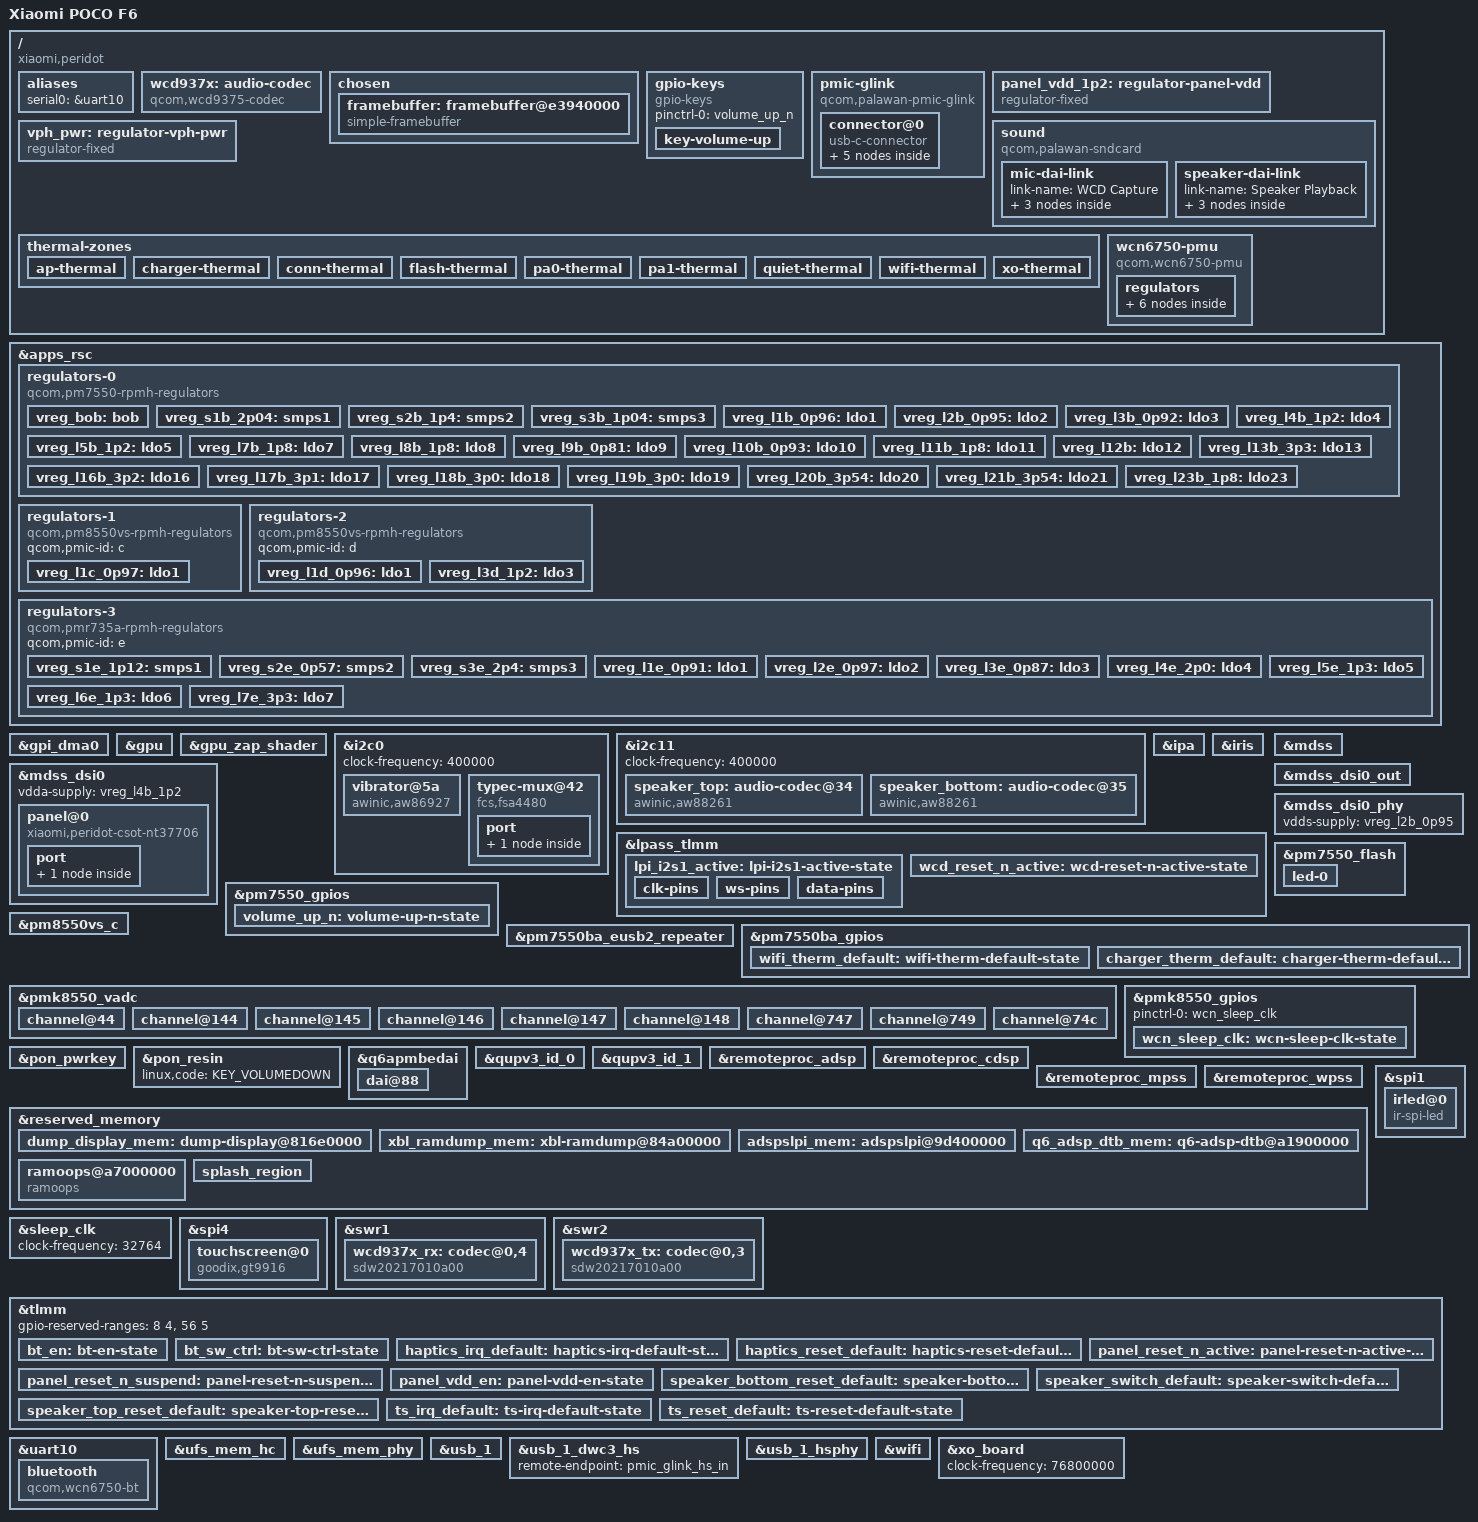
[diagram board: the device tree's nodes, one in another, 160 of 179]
// SPDX-License-Identifier: BSD-3-Clause
/*
 * Copyright (c) 2026, Yassin Rezai <yassinrsocial@proton.me>
 */

/dts-v1/;

#include <dt-bindings/arm/qcom,ids.h>
#include <dt-bindings/leds/common.h>
#include <dt-bindings/pinctrl/qcom,pmic-gpio.h>
#include <dt-bindings/regulator/qcom,rpmh-regulator.h>
#include <dt-bindings/sound/qcom,q6dsp-lpass-ports.h>
#include "palawan.dtsi"
#include "pm7550.dtsi" /* PMXR2230 */
#include "pm7550ba.dtsi"
#include "pmr735a.dtsi"
#define PMK8550VE_SID 3
#include "pm8550ve.dtsi"
#include "pm8550vs.dtsi"
#include "pmk8550.dtsi"

/delete-node/ &adspslpi_mem;
/delete-node/ &q6_adsp_dtb_mem;
/delete-node/ &xbl_ramdump_mem;

/ {
	model = "Xiaomi POCO F6";
	compatible = "xiaomi,peridot", "qcom,palawan";
	chassis-type = "handset";

	/*
	 * The bootloader uses an exact msm-id and board-id match to select
	 * this DTB and skip applying the vendor DTBO.
	 */
	qcom,msm-id = <QCOM_ID_SM8635 0x10000>;
	qcom,board-id = <8 0>;

	aliases {
		serial0 = &uart10;
	};

	wcd937x: audio-codec {
		compatible = "qcom,wcd9375-codec", "qcom,wcd9370-codec";

		reset-gpios = <&lpass_tlmm 12 GPIO_ACTIVE_LOW>;

		vdd-buck-supply = <&vreg_l7b_1p8>;
		vdd-rxtx-supply = <&vreg_l7b_1p8>;
		vdd-px-supply = <&vreg_l7b_1p8>;
		vdd-mic-bias-supply = <&vreg_bob>;

		qcom,micbias1-microvolt = <2750000>;
		qcom,micbias2-microvolt = <2750000>;
		qcom,micbias3-microvolt = <2750000>;
		qcom,micbias4-microvolt = <2750000>;

		qcom,rx-device = <&wcd937x_rx>;
		qcom,tx-device = <&wcd937x_tx>;

		pinctrl-0 = <&wcd_reset_n_active>;
		pinctrl-names = "default";

		#sound-dai-cells = <1>;
	};

	chosen {
		#address-cells = <2>;
		#size-cells = <2>;
		ranges;

		framebuffer: framebuffer@e3940000 {
			compatible = "simple-framebuffer";
			reg = <0x0 0xe3940000 0x0 (1220 * 2712 * 4)>;

			width = <1220>;
			height = <2712>;
			stride = <(1220 * 4)>;
			format = "a8r8g8b8";

			clocks = <&gcc GCC_DISP_HF_AXI_CLK>;
			interconnects = <&mmss_noc MASTER_MDP QCOM_ICC_TAG_ALWAYS
					 &mc_virt SLAVE_EBI1 QCOM_ICC_TAG_ALWAYS>;
			power-domains = <&rpmhpd RPMHPD_MMCX>;
		};
	};

	gpio-keys {
		compatible = "gpio-keys";

		pinctrl-0 = <&volume_up_n>;
		pinctrl-names = "default";

		key-volume-up {
			label = "Volume Up";
			linux,code = <KEY_VOLUMEUP>;
			gpios = <&pm7550_gpios 6 GPIO_ACTIVE_LOW>;
			debounce-interval = <15>;
			linux,can-disable;
			wakeup-source;
		};
	};

	pmic-glink {
		compatible = "qcom,palawan-pmic-glink",
			     "qcom,sm8550-pmic-glink",
			     "qcom,pmic-glink";
		#address-cells = <1>;
		#size-cells = <0>;

		connector@0 {
			compatible = "usb-c-connector";
			reg = <0>;

			power-role = "dual";
			data-role = "dual";

			ports {
				#address-cells = <1>;
				#size-cells = <0>;

				port@0 {
					reg = <0>;

					pmic_glink_hs_in: endpoint {
						remote-endpoint = <&usb_1_dwc3_hs>;
					};
				};

				port@2 {
					reg = <2>;

					pmic_glink_sbu: endpoint {
						remote-endpoint = <&fsa4480_sbu_mux>;
					};
				};
			};
		};
	};

	panel_vdd_1p2: regulator-panel-vdd {
		compatible = "regulator-fixed";

		regulator-name = "panel_vdd_1p2";
		regulator-min-microvolt = <1200000>;
		regulator-max-microvolt = <1200000>;

		gpio = <&tlmm 99 GPIO_ACTIVE_HIGH>;
		enable-active-high;
		regulator-boot-on;

		pinctrl-0 = <&panel_vdd_en>;
		pinctrl-names = "default";
	};

	vph_pwr: regulator-vph-pwr {
		compatible = "regulator-fixed";

		regulator-name = "vph_pwr";
		regulator-min-microvolt = <3700000>;
		regulator-max-microvolt = <3700000>;

		regulator-always-on;
		regulator-boot-on;
	};

	sound {
		compatible = "qcom,palawan-sndcard", "qcom,sm8450-sndcard";
		model = "Xiaomi-Peridot";

		pinctrl-0 = <&lpi_i2s1_active>, <&speaker_switch_default>;
		pinctrl-names = "default";

		audio-routing = "AMIC1", "MIC BIAS1",
				"AMIC2", "MIC BIAS2",
				"AMIC3", "MIC BIAS3",
				"AMIC4", "MIC BIAS3",
				"TX SWR_INPUT0", "ADC1_OUTPUT",
				"TX SWR_INPUT4", "ADC2_OUTPUT",
				"TX SWR_INPUT5", "ADC3_OUTPUT";

		mic-dai-link {
			link-name = "WCD Capture";

			cpu {
				sound-dai = <&q6apmbedai TX_CODEC_DMA_TX_3>;
			};

			codec {
				sound-dai = <&wcd937x 1>, <&swr2 1>, <&lpass_txmacro 0>;
			};

			platform {
				sound-dai = <&q6apm>;
			};
		};

		speaker-dai-link {
			link-name = "Speaker Playback";

			cpu {
				sound-dai = <&q6apmbedai QUINARY_TDM_RX_0>;

				dai-tdm-slot-num = <4>;
				dai-tdm-slot-width = <32>;
				dai-tdm-slot-rx-mask = <1 1 0 0>;
			};

			codec {
				sound-dai = <&speaker_top>, <&speaker_bottom>;

				dai-tdm-slot-num = <4>;
				dai-tdm-slot-width = <32>;
				dai-tdm-slot-rx-mask = <1 1 0 0>;
			};

			platform {
				sound-dai = <&q6apm>;
			};
		};
	};

	thermal-zones {
		ap-thermal {
			thermal-sensors = <&pmk8550_vadc ADC5_GEN3_AMUX2_THM_100K_PU(1)>;
		};

		charger-thermal {
			thermal-sensors = <&pmk8550_vadc ADC5_GEN3_AMUX6_THM_100K_PU(7)>;
		};

		conn-thermal {
			thermal-sensors = <&pmk8550_vadc ADC5_GEN3_AMUX4_THM_100K_PU(7)>;
		};

		flash-thermal {
			thermal-sensors = <&pmk8550_vadc ADC5_GEN3_AMUX5_THM_100K_PU(1)>;
		};

		pa0-thermal {
			thermal-sensors = <&pmk8550_vadc ADC5_GEN3_AMUX1_THM_100K_PU(1)>;
		};

		pa1-thermal {
			thermal-sensors = <&pmk8550_vadc ADC5_GEN3_AMUX3_THM_100K_PU(1)>;
		};

		quiet-thermal {
			thermal-sensors = <&pmk8550_vadc ADC5_GEN3_AMUX4_THM_100K_PU(1)>;
		};

		wifi-thermal {
			thermal-sensors = <&pmk8550_vadc ADC5_GEN3_AMUX3_GPIO_100K_PU(7)>;
		};

		xo-thermal {
			thermal-sensors = <&pmk8550_vadc ADC5_GEN3_AMUX1_THM_100K_PU(0)>;
		};
	};

	wcn6750-pmu {
		compatible = "qcom,wcn6750-pmu";

		pinctrl-0 = <&bt_en>, <&bt_sw_ctrl>;
		pinctrl-names = "default";

		vddio-supply = <&vreg_l7b_1p8>;
		vddaon-supply = <&vreg_s3b_1p04>;
		vddpmu-supply = <&vreg_s3b_1p04>;
		vddrfa0p8-supply = <&vreg_s3b_1p04>;
		vddrfa1p2-supply = <&vreg_s2b_1p4>;
		vddrfa1p7-supply = <&vreg_s1b_2p04>;
		vddrfa2p2-supply = <&vreg_s3e_2p4>;

		bt-enable-gpios = <&tlmm 156 GPIO_ACTIVE_HIGH>;
		swctrl-gpios = <&tlmm 80 GPIO_ACTIVE_HIGH>;

		regulators {
			vreg_pmu_rfa_cmn: ldo0 {
				regulator-name = "vreg_pmu_rfa_cmn";
			};

			vreg_pmu_aon: ldo1 {
				regulator-name = "vreg_pmu_aon";
			};

			vreg_pmu_btcmx: ldo4 {
				regulator-name = "vreg_pmu_btcmx";
			};

			vreg_pmu_rfa_0p8: ldo5 {
				regulator-name = "vreg_pmu_rfa_0p8";
			};

			vreg_pmu_rfa_1p2: ldo6 {
				regulator-name = "vreg_pmu_rfa_1p2";
			};

			vreg_pmu_rfa_1p7: ldo7 {
				regulator-name = "vreg_pmu_rfa_1p7";
			};
		};
	};
};

&apps_rsc {
	regulators-0 {
		compatible = "qcom,pm7550-rpmh-regulators";
		qcom,pmic-id = "b";

		vdd-bob-supply = <&vph_pwr>;

		vreg_bob: bob {
			regulator-name = "vreg_bob";
			regulator-min-microvolt = <3296000>;
			regulator-max-microvolt = <3960000>;
			regulator-initial-mode = <RPMH_REGULATOR_MODE_HPM>;
		};

		vreg_s1b_2p04: smps1 {
			regulator-name = "vreg_s1b_2p04";
			regulator-min-microvolt = <1856000>;
			regulator-max-microvolt = <2040000>;
			regulator-initial-mode = <RPMH_REGULATOR_MODE_HPM>;
		};

		vreg_s2b_1p4: smps2 {
			regulator-name = "vreg_s2b_1p4";
			regulator-min-microvolt = <1256000>;
			regulator-max-microvolt = <1408000>;
			regulator-initial-mode = <RPMH_REGULATOR_MODE_HPM>;
		};

		vreg_s3b_1p04: smps3 {
			regulator-name = "vreg_s3b_1p04";
			regulator-min-microvolt = <968000>;
			regulator-max-microvolt = <1040000>;
			regulator-initial-mode = <RPMH_REGULATOR_MODE_HPM>;
		};

		vreg_l1b_0p96: ldo1 {
			regulator-name = "vreg_l1b_0p96";
			regulator-min-microvolt = <880000>;
			regulator-max-microvolt = <960000>;
			regulator-initial-mode = <RPMH_REGULATOR_MODE_HPM>;
			regulator-allow-set-load;
			regulator-allowed-modes = <RPMH_REGULATOR_MODE_LPM
						   RPMH_REGULATOR_MODE_HPM>;
		};

		vreg_l2b_0p95: ldo2 {
			regulator-name = "vreg_l2b_0p95";
			regulator-min-microvolt = <880000>;
			regulator-max-microvolt = <952000>;
			regulator-initial-mode = <RPMH_REGULATOR_MODE_HPM>;
			regulator-allow-set-load;
			regulator-allowed-modes = <RPMH_REGULATOR_MODE_LPM
						   RPMH_REGULATOR_MODE_HPM>;
		};

		vreg_l3b_0p92: ldo3 {
			regulator-name = "vreg_l3b_0p92";
			regulator-min-microvolt = <880000>;
			regulator-max-microvolt = <920000>;
			regulator-initial-mode = <RPMH_REGULATOR_MODE_HPM>;
			regulator-allow-set-load;
			regulator-allowed-modes = <RPMH_REGULATOR_MODE_LPM
						   RPMH_REGULATOR_MODE_HPM>;
		};

		vreg_l4b_1p2: ldo4 {
			regulator-name = "vreg_l4b_1p2";
			regulator-min-microvolt = <1200000>;
			regulator-max-microvolt = <1200000>;
			regulator-initial-mode = <RPMH_REGULATOR_MODE_HPM>;
			regulator-allow-set-load;
			regulator-allowed-modes = <RPMH_REGULATOR_MODE_LPM
						   RPMH_REGULATOR_MODE_HPM>;
		};

		vreg_l5b_1p2: ldo5 {
			regulator-name = "vreg_l5b_1p2";
			regulator-min-microvolt = <1200000>;
			regulator-max-microvolt = <1200000>;
			regulator-initial-mode = <RPMH_REGULATOR_MODE_HPM>;
			regulator-allow-set-load;
			regulator-allowed-modes = <RPMH_REGULATOR_MODE_LPM
						   RPMH_REGULATOR_MODE_HPM>;
		};

		vreg_l7b_1p8: ldo7 {
			regulator-name = "vreg_l7b_1p8";
			regulator-min-microvolt = <1800000>;
			regulator-max-microvolt = <1800000>;
			regulator-initial-mode = <RPMH_REGULATOR_MODE_HPM>;
			regulator-allow-set-load;
			regulator-allowed-modes = <RPMH_REGULATOR_MODE_LPM
						   RPMH_REGULATOR_MODE_HPM>;
		};

		vreg_l8b_1p8: ldo8 {
			regulator-name = "vreg_l8b_1p8";
			regulator-min-microvolt = <1800000>;
			regulator-max-microvolt = <1800000>;
			regulator-initial-mode = <RPMH_REGULATOR_MODE_HPM>;
			regulator-allow-set-load;
			regulator-allowed-modes = <RPMH_REGULATOR_MODE_LPM
						   RPMH_REGULATOR_MODE_HPM>;
		};

		vreg_l9b_0p81: ldo9 {
			regulator-name = "vreg_l9b_0p81";
			regulator-min-microvolt = <760000>;
			regulator-max-microvolt = <816000>;
			regulator-initial-mode = <RPMH_REGULATOR_MODE_HPM>;
			regulator-allow-set-load;
			regulator-allowed-modes = <RPMH_REGULATOR_MODE_LPM
						   RPMH_REGULATOR_MODE_HPM>;
		};

		vreg_l10b_0p93: ldo10 {
			regulator-name = "vreg_l10b_0p93";
			regulator-min-microvolt = <872000>;
			regulator-max-microvolt = <936000>;
			regulator-initial-mode = <RPMH_REGULATOR_MODE_HPM>;
			regulator-allow-set-load;
			regulator-allowed-modes = <RPMH_REGULATOR_MODE_LPM
						   RPMH_REGULATOR_MODE_HPM>;
		};

		vreg_l11b_1p8: ldo11 {
			regulator-name = "vreg_l11b_1p8";
			regulator-min-microvolt = <1800000>;
			regulator-max-microvolt = <1800000>;
			regulator-initial-mode = <RPMH_REGULATOR_MODE_HPM>;
			regulator-allow-set-load;
			regulator-allowed-modes = <RPMH_REGULATOR_MODE_LPM
						   RPMH_REGULATOR_MODE_HPM>;
		};

		vreg_l12b: ldo12 {
			regulator-name = "vreg_l12b";
			regulator-initial-mode = <RPMH_REGULATOR_MODE_HPM>;
			regulator-allow-set-load;
			regulator-allowed-modes = <RPMH_REGULATOR_MODE_LPM
						   RPMH_REGULATOR_MODE_HPM>;
			/*
			 * The bootloader sets the UFS VCC voltage depending on
			 * the UFS device; UFS is the only consumer and only
			 * votes for enable/disable.
			 */
		};

		vreg_l13b_3p3: ldo13 {
			regulator-name = "vreg_l13b_3p3";
			regulator-min-microvolt = <3296000>;
			regulator-max-microvolt = <3296000>;
			regulator-initial-mode = <RPMH_REGULATOR_MODE_HPM>;
			regulator-allow-set-load;
			regulator-allowed-modes = <RPMH_REGULATOR_MODE_LPM
						   RPMH_REGULATOR_MODE_HPM>;
		};

		vreg_l16b_3p2: ldo16 {
			regulator-name = "vreg_l16b_3p2";
			regulator-min-microvolt = <3200000>;
			regulator-max-microvolt = <3200000>;
			regulator-initial-mode = <RPMH_REGULATOR_MODE_HPM>;
			regulator-allow-set-load;
			regulator-allowed-modes = <RPMH_REGULATOR_MODE_LPM
						   RPMH_REGULATOR_MODE_HPM>;
		};

		vreg_l17b_3p1: ldo17 {
			regulator-name = "vreg_l17b_3p1";
			regulator-min-microvolt = <3072000>;
			regulator-max-microvolt = <3304000>;
			regulator-initial-mode = <RPMH_REGULATOR_MODE_HPM>;
			regulator-allow-set-load;
			regulator-allowed-modes = <RPMH_REGULATOR_MODE_LPM
						   RPMH_REGULATOR_MODE_HPM>;
		};

		vreg_l18b_3p0: ldo18 {
			regulator-name = "vreg_l18b_3p0";
			regulator-min-microvolt = <2000000>;
			regulator-max-microvolt = <3000000>;
			regulator-initial-mode = <RPMH_REGULATOR_MODE_HPM>;
			regulator-allow-set-load;
			regulator-allowed-modes = <RPMH_REGULATOR_MODE_LPM
						   RPMH_REGULATOR_MODE_HPM>;
		};

		vreg_l19b_3p0: ldo19 {
			regulator-name = "vreg_l19b_3p0";
			regulator-min-microvolt = <3000000>;
			regulator-max-microvolt = <3000000>;
			regulator-initial-mode = <RPMH_REGULATOR_MODE_HPM>;
			regulator-allow-set-load;
			regulator-allowed-modes = <RPMH_REGULATOR_MODE_LPM
						   RPMH_REGULATOR_MODE_HPM>;
		};

		vreg_l20b_3p54: ldo20 {
			regulator-name = "vreg_l20b_3p54";
			regulator-min-microvolt = <1624000>;
			regulator-max-microvolt = <3544000>;
			regulator-initial-mode = <RPMH_REGULATOR_MODE_HPM>;
			regulator-allow-set-load;
			regulator-allowed-modes = <RPMH_REGULATOR_MODE_LPM
						   RPMH_REGULATOR_MODE_HPM>;
		};

		vreg_l21b_3p54: ldo21 {
			regulator-name = "vreg_l21b_3p54";
			regulator-min-microvolt = <1624000>;
			regulator-max-microvolt = <3544000>;
			regulator-initial-mode = <RPMH_REGULATOR_MODE_HPM>;
			regulator-allow-set-load;
			regulator-allowed-modes = <RPMH_REGULATOR_MODE_LPM
						   RPMH_REGULATOR_MODE_HPM>;
		};

		vreg_l23b_1p8: ldo23 {
			regulator-name = "vreg_l23b_1p8";
			regulator-min-microvolt = <1800000>;
			regulator-max-microvolt = <1800000>;
			regulator-initial-mode = <RPMH_REGULATOR_MODE_HPM>;
			regulator-allow-set-load;
			regulator-allowed-modes = <RPMH_REGULATOR_MODE_LPM
						   RPMH_REGULATOR_MODE_HPM>;
		};
	};

	regulators-1 {
		compatible = "qcom,pm8550vs-rpmh-regulators";
		qcom,pmic-id = "c";

		vreg_l1c_0p97: ldo1 {
			regulator-name = "vreg_l1c_0p97";
			regulator-min-microvolt = <904000>;
			regulator-max-microvolt = <976000>;
			regulator-initial-mode = <RPMH_REGULATOR_MODE_HPM>;
			regulator-allow-set-load;
			regulator-allowed-modes = <RPMH_REGULATOR_MODE_LPM
						   RPMH_REGULATOR_MODE_HPM>;
		};
	};

	regulators-2 {
		compatible = "qcom,pm8550vs-rpmh-regulators";
		qcom,pmic-id = "d";

		vreg_l1d_0p96: ldo1 {
			regulator-name = "vreg_l1d_0p96";
			regulator-min-microvolt = <872000>;
			regulator-max-microvolt = <960000>;
			regulator-initial-mode = <RPMH_REGULATOR_MODE_HPM>;
			regulator-allow-set-load;
			regulator-allowed-modes = <RPMH_REGULATOR_MODE_LPM
						   RPMH_REGULATOR_MODE_HPM>;
		};

		vreg_l3d_1p2: ldo3 {
			regulator-name = "vreg_l3d_1p2";
			regulator-min-microvolt = <1200000>;
			regulator-max-microvolt = <1200000>;
			regulator-initial-mode = <RPMH_REGULATOR_MODE_HPM>;
			regulator-allow-set-load;
			regulator-allowed-modes = <RPMH_REGULATOR_MODE_LPM
						   RPMH_REGULATOR_MODE_HPM>;
		};
	};

	regulators-3 {
		compatible = "qcom,pmr735a-rpmh-regulators";
		qcom,pmic-id = "e";

		vreg_s1e_1p12: smps1 {
			regulator-name = "vreg_s1e_1p12";
			regulator-min-microvolt = <1012000>;
			regulator-max-microvolt = <1120000>;
			regulator-initial-mode = <RPMH_REGULATOR_MODE_HPM>;
		};

		vreg_s2e_0p57: smps2 {
			regulator-name = "vreg_s2e_0p57";
			regulator-min-microvolt = <300000>;
			regulator-max-microvolt = <572000>;
			regulator-initial-mode = <RPMH_REGULATOR_MODE_HPM>;
		};

		vreg_s3e_2p4: smps3 {
			regulator-name = "vreg_s3e_2p4";
			regulator-min-microvolt = <1600000>;
			regulator-max-microvolt = <2400000>;
			regulator-initial-mode = <RPMH_REGULATOR_MODE_HPM>;
		};

		vreg_l1e_0p91: ldo1 {
			regulator-name = "vreg_l1e_0p91";
			regulator-min-microvolt = <488000>;
			regulator-max-microvolt = <912000>;
			regulator-initial-mode = <RPMH_REGULATOR_MODE_HPM>;
			regulator-allow-set-load;
			regulator-allowed-modes = <RPMH_REGULATOR_MODE_LPM
						   RPMH_REGULATOR_MODE_HPM>;
		};

		vreg_l2e_0p97: ldo2 {
			regulator-name = "vreg_l2e_0p97";
			regulator-min-microvolt = <920000>;
			regulator-max-microvolt = <968000>;
			regulator-initial-mode = <RPMH_REGULATOR_MODE_HPM>;
			regulator-allow-set-load;
			regulator-allowed-modes = <RPMH_REGULATOR_MODE_LPM
						   RPMH_REGULATOR_MODE_HPM>;
		};

		vreg_l3e_0p87: ldo3 {
			regulator-name = "vreg_l3e_0p87";
			regulator-min-microvolt = <504000>;
			regulator-max-microvolt = <872000>;
			regulator-initial-mode = <RPMH_REGULATOR_MODE_HPM>;
			regulator-allow-set-load;
			regulator-allowed-modes = <RPMH_REGULATOR_MODE_LPM
						   RPMH_REGULATOR_MODE_HPM>;
		};

		vreg_l4e_2p0: ldo4 {
			regulator-name = "vreg_l4e_2p0";
			regulator-min-microvolt = <1624000>;
			regulator-max-microvolt = <2000000>;
			regulator-initial-mode = <RPMH_REGULATOR_MODE_HPM>;
			regulator-allow-set-load;
			regulator-allowed-modes = <RPMH_REGULATOR_MODE_LPM
						   RPMH_REGULATOR_MODE_HPM>;
		};

		vreg_l5e_1p3: ldo5 {
			regulator-name = "vreg_l5e_1p3";
			regulator-min-microvolt = <1104000>;
			regulator-max-microvolt = <1304000>;
			regulator-initial-mode = <RPMH_REGULATOR_MODE_HPM>;
			regulator-allow-set-load;
			regulator-allowed-modes = <RPMH_REGULATOR_MODE_LPM
						   RPMH_REGULATOR_MODE_HPM>;
		};

		vreg_l6e_1p3: ldo6 {
			regulator-name = "vreg_l6e_1p3";
			regulator-min-microvolt = <1080000>;
			regulator-max-microvolt = <1304000>;
			regulator-initial-mode = <RPMH_REGULATOR_MODE_HPM>;
			regulator-allow-set-load;
			regulator-allowed-modes = <RPMH_REGULATOR_MODE_LPM
						   RPMH_REGULATOR_MODE_HPM>;
		};

		vreg_l7e_3p3: ldo7 {
			regulator-name = "vreg_l7e_3p3";
			regulator-min-microvolt = <1624000>;
			regulator-max-microvolt = <3304000>;
			regulator-initial-mode = <RPMH_REGULATOR_MODE_HPM>;
			regulator-allow-set-load;
			regulator-allowed-modes = <RPMH_REGULATOR_MODE_LPM
						   RPMH_REGULATOR_MODE_HPM>;
		};
	};
};

&gpi_dma0 {
	status = "okay";
};

&gpu {
	status = "okay";
};

&gpu_zap_shader {
	firmware-name = "qcom/palawan/xiaomi/peridot/gen71100_zap.mbn";
};

&i2c0 {
	clock-frequency = <400000>;

	status = "okay";

	/* Some units use an SiH6887 at 0x6b instead (no driver yet) */
	vibrator@5a {
		compatible = "awinic,aw86927";
		reg = <0x5a>;

		interrupts-extended = <&tlmm 54 IRQ_TYPE_EDGE_FALLING>;
		reset-gpios = <&tlmm 30 GPIO_ACTIVE_LOW>;

		pinctrl-0 = <&haptics_irq_default>, <&haptics_reset_default>;
		pinctrl-names = "default";
	};

	typec-mux@42 {
		compatible = "fcs,fsa4480";
		reg = <0x42>;

		mode-switch;
		orientation-switch;

		port {
			fsa4480_sbu_mux: endpoint {
				remote-endpoint = <&pmic_glink_sbu>;
			};
		};
	};
};

&i2c11 {
	clock-frequency = <400000>;

	status = "okay";

	/* Top speaker, also used as earpiece */
	speaker_top: audio-codec@34 {
		compatible = "awinic,aw88261";
		reg = <0x34>;

		reset-gpios = <&tlmm 76 GPIO_ACTIVE_LOW>;
		/* FIXME: the DVDD rail is not known; L7B is always on */
		dvdd-supply = <&vreg_l7b_1p8>;

		firmware-name = "qcom/palawan/xiaomi/peridot/aw88261_acf.bin";
		sound-name-prefix = "Amplifier Top";

		awinic,audio-channel = <0>;
		awinic,sync-flag;

		pinctrl-0 = <&speaker_top_reset_default>;
		pinctrl-names = "default";

		#sound-dai-cells = <0>;
	};

	/* Bottom speaker */
	speaker_bottom: audio-codec@35 {
		compatible = "awinic,aw88261";
		reg = <0x35>;

		reset-gpios = <&tlmm 152 GPIO_ACTIVE_LOW>;
		dvdd-supply = <&vreg_l7b_1p8>;

		firmware-name = "qcom/palawan/xiaomi/peridot/aw88261_acf.bin";
		sound-name-prefix = "Amplifier Bottom";

		awinic,audio-channel = <1>;
		awinic,sync-flag;

		pinctrl-0 = <&speaker_bottom_reset_default>;
		pinctrl-names = "default";

		#sound-dai-cells = <0>;
	};
};

&ipa {
	firmware-name = "qcom/palawan/xiaomi/peridot/ipa_fws.mbn";

	status = "okay";
};

&iris {
	firmware-name = "qcom/palawan/xiaomi/peridot/vpu30_2v.mbn";

	status = "okay";
};

&lpass_tlmm {
	lpi_i2s1_active: lpi-i2s1-active-state {
		clk-pins {
			pins = "gpio6";
			function = "i2s1_clk";
			drive-strength = <8>;
			bias-disable;
		};

		ws-pins {
			pins = "gpio7";
			function = "i2s1_ws";
			drive-strength = <8>;
			bias-disable;
		};

		data-pins {
			pins = "gpio8", "gpio9";
			function = "i2s1_data";
			drive-strength = <8>;
			bias-disable;
		};
	};

	wcd_reset_n_active: wcd-reset-n-active-state {
		pins = "gpio12";
		function = "gpio";
		drive-strength = <16>;
		bias-disable;
	};
};

&mdss {
	status = "okay";
};

&mdss_dsi0 {
	vdda-supply = <&vreg_l4b_1p2>;

	status = "okay";

	panel@0 {
		compatible = "xiaomi,peridot-csot-nt37706", "novatek,nt37706";
		reg = <0>;

		reset-gpios = <&tlmm 13 GPIO_ACTIVE_LOW>;

		vddio-supply = <&vreg_l8b_1p8>;
		vdd-supply = <&panel_vdd_1p2>;
		vci-supply = <&vreg_l19b_3p0>;

		pinctrl-0 = <&panel_reset_n_active>;
		pinctrl-1 = <&panel_reset_n_suspend>;
		pinctrl-names = "default", "sleep";

		port {
			panel_in: endpoint {
				remote-endpoint = <&mdss_dsi0_out>;
			};
		};
	};
};

&mdss_dsi0_out {
	remote-endpoint = <&panel_in>;
	data-lanes = <0 1 2 3>;
};

&mdss_dsi0_phy {
	vdds-supply = <&vreg_l2b_0p95>;

	status = "okay";
};

&pm7550_flash {
	status = "okay";

	led-0 {
		function = LED_FUNCTION_FLASH;
		color = <LED_COLOR_ID_WHITE>;
		led-sources = <1>, <2>;
		led-max-microamp = <700000>;
		flash-max-microamp = <1000000>;
		flash-max-timeout-us = <300000>;
	};
};

&pm7550_gpios {
	volume_up_n: volume-up-n-state {
		pins = "gpio6";
		function = PMIC_GPIO_FUNC_NORMAL;
		power-source = <1>;
		bias-pull-up;
	};
};

&pm7550ba_eusb2_repeater {
	vdd18-supply = <&vreg_l7b_1p8>;
	vdd3-supply = <&vreg_l17b_3p1>;

	qcom,tune-usb2-amplitude = /bits/ 8 <0xc>;
	qcom,tune-usb2-disc-thres = /bits/ 8 <0x7>;
	qcom,tune-usb2-preem = /bits/ 8 <0x4>;
	qcom,tune-res-fsdif = /bits/ 8 <0x3>;
	qcom,squelch-detector-bp = <(-4000)>;
};

&pm7550ba_gpios {
	wifi_therm_default: wifi-therm-default-state {
		pins = "gpio3";
		function = PMIC_GPIO_FUNC_NORMAL;
		bias-high-impedance;
	};

	charger_therm_default: charger-therm-default-state {
		pins = "gpio6";
		function = PMIC_GPIO_FUNC_NORMAL;
		bias-high-impedance;
	};
};

&pm8550vs_c {
	status = "okay";
};

&pmk8550_vadc {
	pinctrl-0 = <&wifi_therm_default>, <&charger_therm_default>;
	pinctrl-names = "default";

	channel@44 {
		reg = <ADC5_GEN3_AMUX1_THM_100K_PU(0)>;
		label = "pmk8550_xo_therm";
		qcom,ratiometric;
		qcom,hw-settle-time = <200>;
		qcom,pre-scaling = <1 1>;
		qcom,adc-tm;
	};

	channel@144 {
		reg = <ADC5_GEN3_AMUX1_THM_100K_PU(1)>;
		label = "pm7550_pa_therm0";
		qcom,ratiometric;
		qcom,hw-settle-time = <200>;
		qcom,pre-scaling = <1 1>;
		qcom,adc-tm;
	};

	channel@145 {
		reg = <ADC5_GEN3_AMUX2_THM_100K_PU(1)>;
		label = "pm7550_ap_therm";
		qcom,ratiometric;
		qcom,hw-settle-time = <200>;
		qcom,pre-scaling = <1 1>;
		qcom,adc-tm;
	};

	channel@146 {
		reg = <ADC5_GEN3_AMUX3_THM_100K_PU(1)>;
		label = "pm7550_pa_therm1";
		qcom,ratiometric;
		qcom,hw-settle-time = <200>;
		qcom,pre-scaling = <1 1>;
		qcom,adc-tm;
	};

	channel@147 {
		reg = <ADC5_GEN3_AMUX4_THM_100K_PU(1)>;
		label = "pm7550_quiet_therm";
		qcom,ratiometric;
		qcom,hw-settle-time = <200>;
		qcom,pre-scaling = <1 1>;
		qcom,adc-tm;
	};

	channel@148 {
		reg = <ADC5_GEN3_AMUX5_THM_100K_PU(1)>;
		label = "pm7550_flash_therm";
		qcom,ratiometric;
		qcom,hw-settle-time = <200>;
		qcom,pre-scaling = <1 1>;
		qcom,adc-tm;
	};

	channel@747 {
		reg = <ADC5_GEN3_AMUX4_THM_100K_PU(7)>;
		label = "pm7550ba_conn_therm";
		qcom,ratiometric;
		qcom,hw-settle-time = <200>;
		qcom,pre-scaling = <1 1>;
		qcom,adc-tm;
	};

	channel@749 {
		reg = <ADC5_GEN3_AMUX6_THM_100K_PU(7)>;
		label = "pm7550ba_charger_therm";
		qcom,ratiometric;
		qcom,hw-settle-time = <200>;
		qcom,pre-scaling = <1 1>;
		qcom,adc-tm;
	};

	channel@74c {
		reg = <ADC5_GEN3_AMUX3_GPIO_100K_PU(7)>;
		label = "pm7550ba_wifi_therm";
		qcom,ratiometric;
		qcom,hw-settle-time = <200>;
		qcom,pre-scaling = <1 1>;
		qcom,adc-tm;
	};
};

&pmk8550_gpios {
	pinctrl-0 = <&wcn_sleep_clk>;
	pinctrl-names = "default";

	wcn_sleep_clk: wcn-sleep-clk-state {
		pins = "gpio3";
		function = PMIC_GPIO_FUNC_FUNC1;
		input-disable;
		output-enable;
		bias-disable;
		power-source = <0>;
	};
};

&pon_pwrkey {
	status = "okay";
};

&pon_resin {
	linux,code = <KEY_VOLUMEDOWN>;

	status = "okay";
};

&q6apmbedai {
	#address-cells = <1>;
	#size-cells = <0>;

	dai@88 {
		reg = <QUINARY_TDM_RX_0>;
		clocks = <&q6prmcc LPASS_CLK_ID_QUIN_TDM_IBIT LPASS_CLK_ATTRIBUTE_COUPLE_NO>;
		clock-names = "bclk";
	};
};

&qupv3_id_0 {
	status = "okay";
};

&qupv3_id_1 {
	status = "okay";
};

&remoteproc_adsp {
	firmware-name = "qcom/palawan/xiaomi/peridot/adsp.mbn",
			"qcom/palawan/xiaomi/peridot/adsp_dtb.mbn";

	status = "okay";
};

&remoteproc_cdsp {
	firmware-name = "qcom/palawan/xiaomi/peridot/cdsp.mbn",
			"qcom/palawan/xiaomi/peridot/cdsp_dtb.mbn";

	status = "okay";
};

&remoteproc_mpss {
	firmware-name = "qcom/palawan/xiaomi/peridot/modem.mbn",
			"qcom/palawan/xiaomi/peridot/modem_dtb.mbn";

	status = "okay";
};

&remoteproc_wpss {
	firmware-name = "qcom/palawan/xiaomi/peridot/qca6750/wpss.mdt";

	status = "okay";
};

&reserved_memory {
	dump_display_mem: dump-display@816e0000 {
		reg = <0x0 0x816e0000 0x0 0x800>;
		no-map;
	};

	xbl_ramdump_mem: xbl-ramdump@84a00000 {
		reg = <0x0 0x84a00000 0x0 0x200000>;
		no-map;
	};

	adspslpi_mem: adspslpi@9d400000 {
		reg = <0x0 0x9d400000 0x0 0x4500000>;
		no-map;
	};

	q6_adsp_dtb_mem: q6-adsp-dtb@a1900000 {
		reg = <0x0 0xa1900000 0x0 0x80000>;
		no-map;
	};

	/* Layout matches the vendor kernel to share logs across reboots */
	ramoops@a7000000 {
		compatible = "ramoops";
		reg = <0x0 0xa7000000 0x0 0x400000>;
		console-size = <0x200000>;
		pmsg-size = <0x200000>;
	};

	/*
	 * The bootloader looks this node up by its exact path, updates it
	 * with the continuous splash buffer and otherwise powers the display
	 * down before handing over to the kernel.
	 */
	splash_region {
		reg = <0x0 0xe3940000 0x0 0x2b00000>;
		no-map;
	};
};

&sleep_clk {
	clock-frequency = <32764>;
};

&spi1 {
	status = "okay";

	irled@0 {
		compatible = "ir-spi-led";
		reg = <0>;

		spi-max-frequency = <19200000>;
	};
};

&spi4 {
	status = "okay";

	touchscreen@0 {
		compatible = "goodix,gt9916";
		reg = <0>;

		interrupts-extended = <&tlmm 129 IRQ_TYPE_LEVEL_LOW>;
		reset-gpios = <&tlmm 128 GPIO_ACTIVE_LOW>;

		avdd-supply = <&vreg_l13b_3p3>;
		vddio-supply = <&vreg_l23b_1p8>;

		spi-max-frequency = <15000000>;

		/* Reported at 16 times the panel resolution */
		touchscreen-size-x = <19520>;
		touchscreen-size-y = <43392>;

		pinctrl-0 = <&ts_irq_default>, <&ts_reset_default>;
		pinctrl-names = "default";
	};
};

&swr1 {
	status = "okay";

	/* WCD9370 RX */
	wcd937x_rx: codec@0,4 {
		compatible = "sdw20217010a00";
		reg = <0 4>;

		/*
		 * WCD9370 RX Port 1 (HPH_L/R)      <=> SWR1 Port 1 (HPH_L/R)
		 * WCD9370 RX Port 2 (CLSH)         <=> SWR1 Port 2 (CLSH)
		 * WCD9370 RX Port 3 (COMP_L/R)     <=> SWR1 Port 3 (COMP_L/R)
		 * WCD9370 RX Port 4 (LO)           <=> SWR1 Port 4 (LO)
		 * WCD9370 RX Port 5 (DSD_L/R)      <=> SWR1 Port 5 (DSD_L/R)
		 */
		qcom,rx-port-mapping = <1 2 3 4 5>;
	};
};

&swr2 {
	/*
	 * The WCD9375 only uses data lanes 0 and 1: as in the vendor
	 * configuration, put ADC1 on lane 0 (offset 1, after the control
	 * column) and ADC2/3 on lane 1.
	 */
	qcom,ports-offset1 = /bits/ 8 <0x00 0x01 0x00 0x01 0x01>;
	qcom,ports-lane-control = /bits/ 8 <0xff 0x00 0x01 0x00 0x00>;

	status = "okay";

	/* WCD9370 TX */
	wcd937x_tx: codec@0,3 {
		compatible = "sdw20217010a00";
		reg = <0 3>;

		/*
		 * WCD9370 TX Port 1 (ADC1)               <=> SWR2 Port 2 (TX SWR_INPUT 0-3)
		 * WCD9370 TX Port 2 (ADC2, 3)            <=> SWR2 Port 3 (TX SWR_INPUT 4-7)
		 * WCD9370 TX Port 3 (DMIC0,1,2,3 & MBHC) <=> SWR2 Port 4 (TX SWR_INPUT 8-11)
		 * WCD9370 TX Port 4 (DMIC4,5,6,7)        <=> SWR2 Port 5
		 */
		qcom,tx-port-mapping = <2 3 4 5>;
	};
};

&tlmm {
	gpio-reserved-ranges = <8 4>, <56 5>;

	bt_en: bt-en-state {
		pins = "gpio156";
		function = "gpio";
		drive-strength = <2>;
		bias-pull-down;
		output-low;
	};

	bt_sw_ctrl: bt-sw-ctrl-state {
		pins = "gpio80";
		function = "gpio";
		drive-strength = <2>;
		bias-pull-down;
	};

	haptics_irq_default: haptics-irq-default-state {
		pins = "gpio54";
		function = "gpio";
		drive-strength = <2>;
		bias-pull-up;
	};

	haptics_reset_default: haptics-reset-default-state {
		pins = "gpio30";
		function = "gpio";
		drive-strength = <2>;
		bias-disable;
	};

	panel_reset_n_active: panel-reset-n-active-state {
		pins = "gpio13";
		function = "gpio";
		drive-strength = <8>;
		bias-disable;
	};

	panel_reset_n_suspend: panel-reset-n-suspend-state {
		pins = "gpio13";
		function = "gpio";
		drive-strength = <2>;
		bias-pull-down;
	};

	panel_vdd_en: panel-vdd-en-state {
		pins = "gpio99";
		function = "gpio";
		drive-strength = <2>;
		bias-disable;
	};

	speaker_bottom_reset_default: speaker-bottom-reset-default-state {
		pins = "gpio152";
		function = "gpio";
		drive-strength = <2>;
		bias-disable;
	};

	/* Low routes the top amplifier to the speaker, high to the earpiece */
	speaker_switch_default: speaker-switch-default-state {
		pins = "gpio98";
		function = "gpio";
		drive-strength = <2>;
		bias-disable;
		output-low;
	};

	speaker_top_reset_default: speaker-top-reset-default-state {
		pins = "gpio76";
		function = "gpio";
		drive-strength = <2>;
		bias-disable;
	};

	ts_irq_default: ts-irq-default-state {
		pins = "gpio129";
		function = "gpio";
		drive-strength = <2>;
		bias-disable;
		output-disable;
	};

	ts_reset_default: ts-reset-default-state {
		pins = "gpio128";
		function = "gpio";
		drive-strength = <6>;
		bias-disable;
	};
};

&uart10 {
	status = "okay";

	bluetooth {
		compatible = "qcom,wcn6750-bt";
		max-speed = <3200000>;

		vddaon-supply = <&vreg_pmu_aon>;
		vddbtcmx-supply = <&vreg_pmu_btcmx>;
		vddrfa0p8-supply = <&vreg_pmu_rfa_0p8>;
		vddrfa1p2-supply = <&vreg_pmu_rfa_1p2>;
		vddrfa1p7-supply = <&vreg_pmu_rfa_1p7>;
		vddrfacmn-supply = <&vreg_pmu_rfa_cmn>;
	};
};

&ufs_mem_hc {
	reset-gpios = <&tlmm 178 GPIO_ACTIVE_LOW>;

	vcc-supply = <&vreg_l12b>;
	vcc-max-microamp = <1200000>;
	vccq-supply = <&vreg_l3d_1p2>;
	vccq-max-microamp = <1200000>;

	status = "okay";
};

&ufs_mem_phy {
	vdda-phy-supply = <&vreg_l1d_0p96>;
	vdda-pll-supply = <&vreg_l4b_1p2>;

	status = "okay";
};

&usb_1 {
	/* USB 2.0 only receptacle */
	dr_mode = "otg";
	usb-role-switch;
	maximum-speed = "high-speed";

	phys = <&usb_1_hsphy>;
	phy-names = "usb2-phy";

	/* No SuperSpeed PHY: clock the core from UTMI instead of the pipe clock */
	qcom,select-utmi-as-pipe-clk;

	status = "okay";
};

&usb_1_dwc3_hs {
	remote-endpoint = <&pmic_glink_hs_in>;
};

&usb_1_hsphy {
	vdd-supply = <&vreg_l2b_0p95>;
	vdda12-supply = <&vreg_l4b_1p2>;

	phys = <&pm7550ba_eusb2_repeater>;

	status = "okay";
};

&wifi {
	status = "okay";
};

&xo_board {
	clock-frequency = <76800000>;
};
